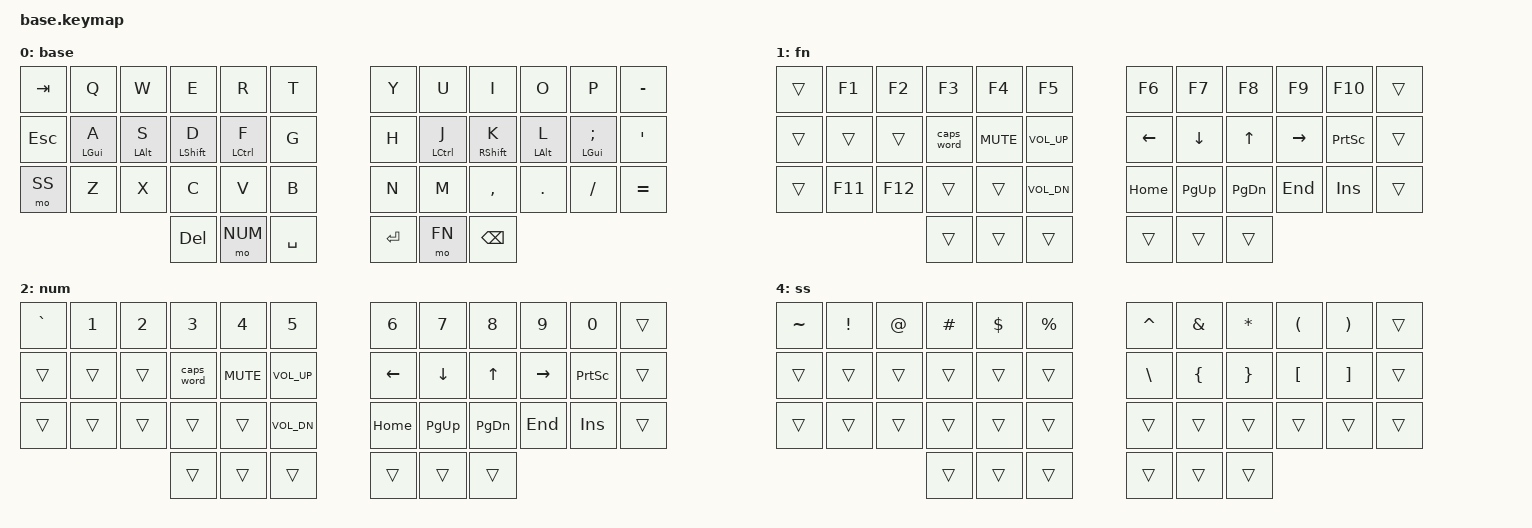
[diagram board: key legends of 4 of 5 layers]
#include <behaviors.dtsi>
#include <dt-bindings/zmk/keys.h>

#define CONFIG_WIRELESS

#ifdef CONFIG_WIRELESS
    #include <dt-bindings/zmk/bt.h>
    #define _BT_SEL_KEYS_ &bt BT_SEL 0 &bt BT_SEL 1 &bt BT_SEL 2 &bt BT_SEL 3 &bt BT_CLR
#else
    #define _BT_SEL_KEYS_ &trans &trans &trans &trans &trans
#endif

#include "zmk-helpers/helper.h"
#include "zmk-helpers/key-labels/42.h"

#define DEF 0
#define FN 1
#define NUM 2
#define SYS 3
#define SS 4

#define XXX &none
#define ___ &trans

/* Global settings */

#define QUICK_TAP_MS 175

/* Homerow mods */

#define KEYS_L LT0 LT1 LT2 LT3 LT4 LT5 LM0 LM1 LM2 LM3 LM4 LM5 LB0 LB1 LB2 LB3 LB4 LB5 // left hand
#define KEYS_R RT0 RT1 RT2 RT3 RT4 RT5 RM0 RM1 RM2 RM3 RM4 RM5 RB0 RB1 RB2 RB3 RB4 RB5 // right hand
#define THUMBS LH2 LH1 LH0 RH0 RH1 RH2                                      // thumbs

#define MAKE_HRM(NAME, HOLD, TAP, TRIGGER_POS) \
    ZMK_HOLD_TAP(NAME, \
        flavor = "balanced"; \
        tapping-term-ms = <280>; \
        quick-tap-ms = <QUICK_TAP_MS>; \
        require-prior-idle-ms = <150>; \
        bindings = <HOLD>, <TAP>; \
        hold-trigger-key-positions = <TRIGGER_POS>; \
        hold-trigger-on-release; \
    )
MAKE_HRM(hml, &kp, &kp, KEYS_R THUMBS)  // left-hand HRMs
MAKE_HRM(hmr, &kp, &kp, KEYS_L THUMBS)  // right-hand HRMs

&caps_word {  // mods deactivate caps-word, requires PR #1451
    /delete-property/ ignore-modifiers;
};

/* Keymap */

ZMK_CONDITIONAL_LAYER(sys, NUM FN, SYS)  // FN + NUM --> SYS

ZMK_LAYER(base,
//╭────────────────┬────────────────┬────────────────┬────────────────┬────────────────┬────────────────╮                 ╭────────────────┬────────────────┬────────────────┬────────────────┬────────────────┬────────────────╮
    &kp TAB          &kp Q            &kp W            &kp E            &kp R            &kp T                              &kp Y            &kp U            &kp I            &kp O            &kp P            &kp MINUS
//├────────────────┼────────────────┼────────────────┼────────────────┼────────────────┼────────────────┤                 ├────────────────┼────────────────┼────────────────┼────────────────┼────────────────┼────────────────┤
    &kp ESC          &hml LGUI A      &hml LALT S      &hml LSHFT D     &hml LCTRL F     &kp G                              &kp H            &hmr LCTRL J     &hmr RSHFT K     &hmr LALT L      &hmr LGUI SEMI   &kp APOS
//├────────────────┼────────────────┼────────────────┼────────────────┼────────────────┼────────────────┤                 ├────────────────┼────────────────┼────────────────┼────────────────┼────────────────┼────────────────┤
    &mo SS           &kp Z            &kp X            &kp C            &kp V            &kp B                              &kp N            &kp M            &kp COMMA        &kp PERIOD       &kp FSLH         &kp EQUAL
//╰────────────────┴────────────────┴────────────────┼────────────────┼────────────────┼────────────────┤                 ├────────────────┼────────────────┼────────────────┴────────────────┴────────────────┴────────────────╯
                                                       &kp DEL          &mo NUM          &kp SPC                            &kp RET          &mo FN           &kp BSPC
//                                                   ╰────────────────┴────────────────┴────────────────╯                 ╰────────────────┴────────────────┴────────────────╯
)

ZMK_LAYER(fn,
//╭──────────────┬──────────────┬──────────────┬──────────────┬──────────────┬──────────────╮               ╭──────────────┬──────────────┬──────────────┬──────────────┬──────────────┬──────────────╮
    ___            &kp F1         &kp F2         &kp F3         &kp F4         &kp F5                         &kp F6         &kp F7         &kp F8         &kp F9         &kp F10        ___
//├──────────────┼──────────────┼──────────────┼──────────────┼──────────────┼──────────────┤               ├──────────────┼──────────────┼──────────────┼──────────────┼──────────────┼──────────────┤
    ___            ___            ___            &caps_word     &kp C_MUTE     &kp C_VOL_UP                   &kp LEFT       &kp DOWN       &kp UP         &kp RIGHT      &kp PSCRN      ___
//├──────────────┼──────────────┼──────────────┼──────────────┼──────────────┼──────────────┤               ├──────────────┼──────────────┼──────────────┼──────────────┼──────────────┼──────────────┤
    ___            &kp F11        &kp F12        ___            ___            &kp C_VOL_DN                   &kp HOME       &kp PG_UP      &kp PG_DN      &kp END        &kp INS        ___
//╰──────────────┴──────────────┴──────────────┼──────────────┼──────────────┼──────────────┤               ├──────────────┼──────────────┼──────────────┴──────────────┴──────────────┴──────────────╯
                                                 ___            ___            ___                            ___            ___            ___
//                                             ╰──────────────┴──────────────┴──────────────╯               ╰──────────────┴──────────────┴──────────────╯
)

ZMK_LAYER(num,
//╭──────────────┬──────────────┬──────────────┬──────────────┬──────────────┬──────────────╮               ╭──────────────┬──────────────┬──────────────┬──────────────┬──────────────┬──────────────╮
    &kp GRAVE      &kp N1         &kp N2         &kp N3         &kp N4         &kp N5                         &kp N6         &kp N7         &kp N8         &kp N9         &kp N0         ___
//├──────────────┼──────────────┼──────────────┼──────────────┼──────────────┼──────────────┤               ├──────────────┼──────────────┼──────────────┼──────────────┼──────────────┼──────────────┤
    ___            ___            ___            &caps_word     &kp C_MUTE     &kp C_VOL_UP                   &kp LEFT       &kp DOWN       &kp UP         &kp RIGHT      &kp PSCRN      ___
//├──────────────┼──────────────┼──────────────┼──────────────┼──────────────┼──────────────┤               ├──────────────┼──────────────┼──────────────┼──────────────┼──────────────┼──────────────┤
    ___            ___            ___            ___            ___            &kp C_VOL_DN                   &kp HOME       &kp PG_UP      &kp PG_DN      &kp END        &kp INS        ___
//╰──────────────┴──────────────┴──────────────┼──────────────┼──────────────┼──────────────┤               ├──────────────┼──────────────┼──────────────┴──────────────┴──────────────┴──────────────╯
                                                 ___            ___            ___                            ___            ___            ___
//                                             ╰──────────────┴──────────────┴──────────────╯               ╰──────────────┴──────────────┴──────────────╯
)

ZMK_LAYER(sys,
//╭───────────────┬───────────────┬───────────────┬───────────────┬───────────────┬───────────────╮                ╭───────────────┬───────────────┬───────────────┬───────────────┬───────────────┬───────────────╮
    ___                                              _BT_SEL_KEYS_                                                   ___             ___             ___             ___             ___             ___
//├───────────────┼───────────────┼───────────────┼───────────────┼───────────────┼───────────────┤                ├───────────────┼───────────────┼───────────────┼───────────────┼───────────────┼───────────────┤
    ___             ___             ___             ___             ___             &bootloader                      &bootloader     ___             ___             ___             ___             ___
//├───────────────┼───────────────┼───────────────┼───────────────┼───────────────┼───────────────┤                ├───────────────┼───────────────┼───────────────┼───────────────┼───────────────┼───────────────┤
    ___             ___             ___             ___             ___             &sys_reset                       &sys_reset      ___             ___             ___             ___             ___
//╰───────────────┴───────────────┴───────────────┼───────────────┼───────────────┼───────────────┤                ├───────────────┼───────────────┼───────────────┴───────────────┴───────────────┴───────────────╯
                                                    ___             ___             ___                              ___             ___             ___
//                                                ╰───────────────┴───────────────┴───────────────╯                ╰───────────────┴───────────────┴───────────────╯
)

ZMK_LAYER(ss,
//╭───────────┬───────────┬───────────┬───────────┬───────────┬───────────╮            ╭───────────┬───────────┬───────────┬───────────┬───────────┬───────────╮
    &kp TILDE   &kp EXCL    &kp AT      &kp HASH    &kp DLLR    &kp PRCNT                &kp CARET   &kp AMPS    &kp ASTRK   &kp LPAR    &kp RPAR    ___
//├───────────┼───────────┼───────────┼───────────┼───────────┼───────────┤            ├───────────┼───────────┼───────────┼───────────┼───────────┼───────────┤
    ___         ___         ___         ___         ___         ___                      &kp BSLH    &kp LBRC    &kp RBRC    &kp LBKT    &kp RBKT    ___
//├───────────┼───────────┼───────────┼───────────┼───────────┼───────────┤            ├───────────┼───────────┼───────────┼───────────┼───────────┼───────────┤
    ___         ___         ___         ___         ___         ___                      ___         ___         ___         ___         ___         ___
//╰───────────┴───────────┴───────────┼───────────┼───────────┼───────────┤            ├───────────┼───────────┼───────────┴───────────┴───────────┴───────────╯
                                        ___         ___         ___                      ___         ___         ___
//                                    ╰───────────┴───────────┴───────────╯            ╰───────────┴───────────┴───────────╯
)

/* vim: set ft=c tw=174: */
